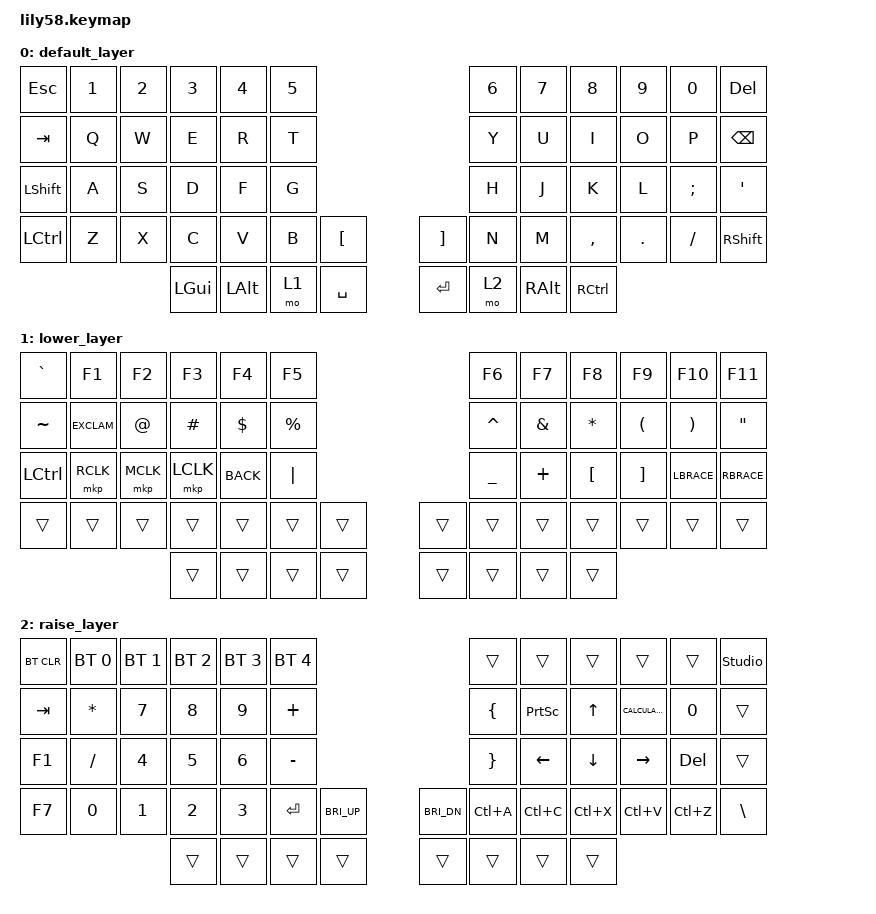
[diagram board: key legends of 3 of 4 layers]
/*
 * Copyright (c) 2020 The ZMK Contributors
 *
 * SPDX-License-Identifier: MIT
 */

#include <behaviors.dtsi>
#include <dt-bindings/zmk/bt.h>
#include <dt-bindings/zmk/keys.h>
#include <dt-bindings/zmk/pointing.h>

/ {
    keymap {
        compatible = "zmk,keymap";

        default_layer {
            bindings = <
                &kp ESC           &kp N1  &kp N2  &kp N3        &kp N4        &kp N5                         &kp N6  &kp N7         &kp N8             &kp N9   &kp N0    &kp DEL
                &kp TAB           &kp Q   &kp W   &kp E         &kp R         &kp T                          &kp Y   &kp U          &kp I              &kp O    &kp P     &kp BACKSPACE
                &kp LEFT_SHIFT    &kp A   &kp S   &kp D         &kp F         &kp G                          &kp H   &kp J          &kp K              &kp L    &kp SEMI  &kp SQT
                &kp LEFT_CONTROL  &kp Z   &kp X   &kp C         &kp V         &kp B   &kp LBKT     &kp RBKT  &kp N   &kp M          &kp COMMA          &kp DOT  &kp FSLH  &kp RSHFT
                                      &kp LEFT_GUI  &kp LEFT_ALT  &mo 1   &kp SPACE    &kp RET   &mo 2   &kp RIGHT_ALT  &kp RIGHT_CONTROL
            >;
        };

        lower_layer {
            bindings = <
                &kp GRAVE         &kp F1         &kp F2         &kp F3         &kp F4        &kp F5                         &kp F6            &kp F7             &kp F8          &kp F9           &kp F10               &kp F11
                &kp TILDE         &kp EXCLAM     &kp AT         &kp HASH       &kp DLLR      &kp PERCENT                    &kp CARET         &kp AMPS           &kp ASTRK       &kp LPAR         &kp RPAR              &kp DOUBLE_QUOTES
                &kp LEFT_CONTROL  &mkp RCLK      &mkp MCLK      &mkp LCLK      &kp K_BACK    &kp PIPE                        &kp UNDERSCORE    &kp PLUS           &kp LBKT        &kp RBKT         &kp LBRACE            &kp RBRACE
                &trans            &trans         &trans         &trans         &trans        &trans    &trans        &trans    &trans         &trans           &trans          &trans        &trans     &trans
                                               &trans         &trans        &trans      &trans        &trans           &trans            &trans             &trans
            >;
            sensor-bindings = <&inc_dec_kp C_VOL_UP C_VOL_DN>;
        };

        raise_layer {
            bindings = <
                &bt BT_CLR        &bt BT_SEL 0   &bt BT_SEL 1   &bt BT_SEL 2   &bt BT_SEL 3  &bt BT_SEL 4                    &trans           &trans           &trans        &trans            &trans     &studio_unlock
                &kp TAB           &kp ASTERISK   &kp N7         &kp N8         &kp N9        &kp PLUS                        &kp LEFT_BRACE   &kp PRINTSCREEN  &kp UP_ARROW  &kp K_CALCULATOR  &kp N0     &trans&kp F1            &kp SLASH      &kp N4         &kp N5         &kp N6        &kp MINUS                       &kp RIGHT_BRACE  &kp LEFT         &kp DOWN      &kp RIGHT         &kp DEL    &trans
                &kp F7            &kp N0         &kp N1         &kp N2         &kp N3        &kp RET      &kp C_BRI_UP    &kp C_BRI_DN  &kp LC(A)        &kp LC(C)        &kp LC(X)     &kp LC(V)         &kp LC(Z)  &kp BSLH
                                             &trans        &trans        &trans        &trans          &trans        &trans           &trans           &trans
            >;
            sensor-bindings = <&inc_dec_kp C_VOL_UP C_VOL_DN>;
        };

        mouse_layer {
            bindings = <
                &mkp MOVE_UP     &mkp LCLK      &mkp MCLK      &mkp RCLK      &mkp SCROLL_UP
                &mkp MOVE_LEFT   &mkp MOVE_DOWN &mkp MOVE_RIGHT &mkp SCROLL_DOWN &none
                &none           &none          &none          &none          &none
                &none           &none          &none          &none          &none &none &none &none &none &none &none &none &none &none
                                     &trans       &trans        &trans        &trans       &trans     &trans        &trans         &trans
            >;
        };
    };
};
